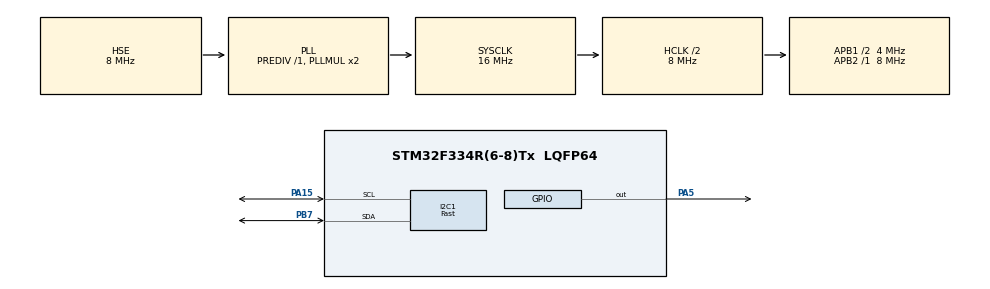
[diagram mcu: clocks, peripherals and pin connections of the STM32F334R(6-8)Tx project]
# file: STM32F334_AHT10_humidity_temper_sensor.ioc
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I2C1.I2C_Speed_Mode=I2C_Fast
I2C1.Timing=0x0000020B
Mcu.Family=STM32F3
Mcu.Name=STM32F334R(6-8)Tx
Mcu.Package=LQFP64
NVIC.I2C1_EV_IRQn=true\:0\:0\:false\:false\:true\:true\:true
NVIC.PriorityGroup=NVIC_PRIORITYGROUP_4
NVIC.TIM3_IRQn=true\:0\:0\:false\:false\:true\:true\:true
PA13.Mode=Serial_Wire
PA13.Signal=SYS_JTMS-SWDIO
PA14.Mode=Serial_Wire
PA14.Signal=SYS_JTCK-SWCLK
PA15.Mode=I2C
PA15.Signal=I2C1_SCL
PA5.Signal=GPIO_Output
PB7.Mode=I2C
PB7.Signal=I2C1_SDA
PF0\ /\ OSC_IN.Mode=HSE-External-Clock-Source
PF0\ /\ OSC_IN.Signal=RCC_OSC_IN
ProjectManager.HeapSize=0x200
ProjectManager.StackSize=0x400
ProjectManager.TargetToolchain=STM32CubeIDE
RCC.AHBCLKDivider=RCC_SYSCLK_DIV2
RCC.AHBFreq_Value=8000000
RCC.APB1CLKDivider=RCC_HCLK_DIV2
RCC.APB1Freq_Value=4000000
RCC.APB1TimFreq_Value=8000000
RCC.APB2Freq_Value=8000000
RCC.APB2TimFreq_Value=8000000
RCC.CortexFreq_Value=8000000
RCC.HCLKFreq_Value=8000000
RCC.HSE_VALUE=8000000
RCC.HSI_VALUE=8000000
RCC.LSE_VALUE=32768
RCC.PLLSourceVirtual=RCC_PLLSOURCE_HSE
RCC.SYSCLKFreq_VALUE=16000000
RCC.SYSCLKSourceVirtual=RCC_SYSCLKSOURCE_PLLCLK
TIM3.Period=1000-1
TIM3.Prescaler=800-1
VP_TIM3_VS_ClockSourceINT.Mode=Internal
board=custom

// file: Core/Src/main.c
/* USER CODE BEGIN Header */
/**
 ******************************************************************************
 * @file           : main.c
 * @brief          : Main program body
 ******************************************************************************
 * @attention
 *
 * <h2><center>&copy; Copyright (c) 2020 STMicroelectronics.
 * All rights reserved.</center></h2>
 *
 * This software component is licensed by ST under BSD 3-Clause license,
 * the "License"; You may not use this file except in compliance with the
 * License. You may obtain a copy of the License at:
 *                        opensource.org/licenses/BSD-3-Clause
 *
 ******************************************************************************
 */
/* USER CODE END Header */
#include "main.h"

I2C_HandleTypeDef hi2c1;

TIM_HandleTypeDef htim3;

/* USER CODE BEGIN PV */

/*Змінні необхідні для AHT10*/
uint8_t AHT10_RX_Data[6];
uint32_t AHT10_ADC_RAW;
float AHT10_Temperature;
float AHT10_Humidity;
uint8_t AHT10_TmpHumCmd[3] = { 0xAC, 0x33, 0x00 };

#define AHT10_ADDRESS (0x38 << 1)

/*Додаткові змінні*/
uint8_t T_100ms = 255;
uint8_t AHT10_Switcher = 255;

/* USER CODE END PV */

void SystemClock_Config(void);
static void MX_GPIO_Init(void);
static void MX_I2C1_Init(void);
static void MX_TIM3_Init(void);

/* USER CODE BEGIN 0 */
void HAL_TIM_PeriodElapsedCallback(TIM_HandleTypeDef *htim) {
	if (htim->Instance == TIM3) {
		T_100ms = 255;

	}
}
/* USER CODE END 0 */

int main(void) {

	/* MCU Configuration--------------------------------------------------------*/

	/* Reset of all peripherals, Initializes the Flash interface and the Systick. */
	HAL_Init();

	/* Configure the system clock */
	SystemClock_Config();

	/* Initialize all configured peripherals */
	MX_GPIO_Init();
	MX_I2C1_Init();
	MX_TIM3_Init();
	/* USER CODE BEGIN 2 */
	HAL_TIM_Base_Start_IT(&htim3);
	/* USER CODE END 2 */

	/* Infinite loop */
	/* USER CODE BEGIN WHILE */
	while (1) {

		if (T_100ms) {
			if (AHT10_Switcher) {
				HAL_I2C_Master_Transmit_IT(&hi2c1, AHT10_ADDRESS,
						(uint8_t*) AHT10_TmpHumCmd, 3);
			} else {
				HAL_I2C_Master_Receive_IT(&hi2c1, AHT10_ADDRESS,
						(uint8_t*) AHT10_RX_Data, 6);

			}

			if (~AHT10_RX_Data[0] & 0x80) {
				/* Convert to Temperature in °C */
				AHT10_ADC_RAW = (((uint32_t) AHT10_RX_Data[3] & 15) << 16)
						| ((uint32_t) AHT10_RX_Data[4] << 8) | AHT10_RX_Data[5];
				AHT10_Temperature =
						(float) (AHT10_ADC_RAW * 200.00 / 1048576.00) - 50.00;
				/* Convert to Relative Humidity in % */
				AHT10_ADC_RAW = ((uint32_t) AHT10_RX_Data[1] << 12)
						| ((uint32_t) AHT10_RX_Data[2] << 4)
						| (AHT10_RX_Data[3] >> 4);
				AHT10_Humidity = (float) (AHT10_ADC_RAW * 100.00 / 1048576.00);
			}

			/* Invert */
			AHT10_Switcher = ~AHT10_Switcher;
			/* Nullify */
			T_100ms = 0;
			GPIOA->ODR ^= GPIO_PIN_5;
		}

		/* USER CODE END WHILE */

	}
}

void SystemClock_Config(void) {
	RCC_OscInitTypeDef RCC_OscInitStruct = { 0 };
	RCC_ClkInitTypeDef RCC_ClkInitStruct = { 0 };
	RCC_PeriphCLKInitTypeDef PeriphClkInit = { 0 };

	/** Initializes the RCC Oscillators according to the specified parameters
	 * in the RCC_OscInitTypeDef structure.
	 */
	RCC_OscInitStruct.OscillatorType = RCC_OSCILLATORTYPE_HSI
			| RCC_OSCILLATORTYPE_HSE;
	RCC_OscInitStruct.HSEState = RCC_HSE_BYPASS;
	RCC_OscInitStruct.HSEPredivValue = RCC_HSE_PREDIV_DIV1;
	RCC_OscInitStruct.HSIState = RCC_HSI_ON;
	RCC_OscInitStruct.HSICalibrationValue = RCC_HSICALIBRATION_DEFAULT;
	RCC_OscInitStruct.PLL.PLLState = RCC_PLL_ON;
	RCC_OscInitStruct.PLL.PLLSource = RCC_PLLSOURCE_HSE;
	RCC_OscInitStruct.PLL.PLLMUL = RCC_PLL_MUL2;
	if (HAL_RCC_OscConfig(&RCC_OscInitStruct) != HAL_OK) {
		Error_Handler();
	}
	/** Initializes the CPU, AHB and APB buses clocks
	 */
	RCC_ClkInitStruct.ClockType = RCC_CLOCKTYPE_HCLK | RCC_CLOCKTYPE_SYSCLK
			| RCC_CLOCKTYPE_PCLK1 | RCC_CLOCKTYPE_PCLK2;
	RCC_ClkInitStruct.SYSCLKSource = RCC_SYSCLKSOURCE_PLLCLK;
	RCC_ClkInitStruct.AHBCLKDivider = RCC_SYSCLK_DIV2;
	RCC_ClkInitStruct.APB1CLKDivider = RCC_HCLK_DIV2;
	RCC_ClkInitStruct.APB2CLKDivider = RCC_HCLK_DIV1;

	if (HAL_RCC_ClockConfig(&RCC_ClkInitStruct, FLASH_LATENCY_0) != HAL_OK) {
		Error_Handler();
	}
	PeriphClkInit.PeriphClockSelection = RCC_PERIPHCLK_I2C1;
	PeriphClkInit.I2c1ClockSelection = RCC_I2C1CLKSOURCE_HSI;
	if (HAL_RCCEx_PeriphCLKConfig(&PeriphClkInit) != HAL_OK) {
		Error_Handler();
	}
}

static void MX_I2C1_Init(void) {

	hi2c1.Instance = I2C1;
	hi2c1.Init.Timing = 0x0000020B;
	hi2c1.Init.OwnAddress1 = 0;
	hi2c1.Init.AddressingMode = I2C_ADDRESSINGMODE_7BIT;
	hi2c1.Init.DualAddressMode = I2C_DUALADDRESS_DISABLE;
	hi2c1.Init.OwnAddress2 = 0;
	hi2c1.Init.OwnAddress2Masks = I2C_OA2_NOMASK;
	hi2c1.Init.GeneralCallMode = I2C_GENERALCALL_DISABLE;
	hi2c1.Init.NoStretchMode = I2C_NOSTRETCH_DISABLE;
	if (HAL_I2C_Init(&hi2c1) != HAL_OK) {
		Error_Handler();
	}
	/** Configure Analogue filter
	 */
	if (HAL_I2CEx_ConfigAnalogFilter(&hi2c1, I2C_ANALOGFILTER_ENABLE)
			!= HAL_OK) {
		Error_Handler();
	}
	/** Configure Digital filter
	 */
	if (HAL_I2CEx_ConfigDigitalFilter(&hi2c1, 0) != HAL_OK) {
		Error_Handler();
	}

}

static void MX_TIM3_Init(void) {

	TIM_ClockConfigTypeDef sClockSourceConfig = { 0 };
	TIM_MasterConfigTypeDef sMasterConfig = { 0 };

	htim3.Instance = TIM3;
	htim3.Init.Prescaler = 800 - 1;
	htim3.Init.CounterMode = TIM_COUNTERMODE_UP;
	htim3.Init.Period = 1000 - 1;
	htim3.Init.ClockDivision = TIM_CLOCKDIVISION_DIV1;
	htim3.Init.AutoReloadPreload = TIM_AUTORELOAD_PRELOAD_DISABLE;
	if (HAL_TIM_Base_Init(&htim3) != HAL_OK) {
		Error_Handler();
	}
	sClockSourceConfig.ClockSource = TIM_CLOCKSOURCE_INTERNAL;
	if (HAL_TIM_ConfigClockSource(&htim3, &sClockSourceConfig) != HAL_OK) {
		Error_Handler();
	}
	sMasterConfig.MasterOutputTrigger = TIM_TRGO_RESET;
	sMasterConfig.MasterSlaveMode = TIM_MASTERSLAVEMODE_DISABLE;
	if (HAL_TIMEx_MasterConfigSynchronization(&htim3, &sMasterConfig)
			!= HAL_OK) {
		Error_Handler();
	}

}

static void MX_GPIO_Init(void) {
	GPIO_InitTypeDef GPIO_InitStruct = { 0 };

	/* GPIO Ports Clock Enable */
	__HAL_RCC_GPIOF_CLK_ENABLE();
	__HAL_RCC_GPIOA_CLK_ENABLE();
	__HAL_RCC_GPIOB_CLK_ENABLE();

	/*Configure GPIO pin Output Level */
	HAL_GPIO_WritePin(GPIOA, GPIO_PIN_5, GPIO_PIN_RESET);

	/*Configure GPIO pin : PA5 */
	GPIO_InitStruct.Pin = GPIO_PIN_5;
	GPIO_InitStruct.Mode = GPIO_MODE_OUTPUT_PP;
	GPIO_InitStruct.Pull = GPIO_NOPULL;
	GPIO_InitStruct.Speed = GPIO_SPEED_FREQ_LOW;
	HAL_GPIO_Init(GPIOA, &GPIO_InitStruct);

}

void Error_Handler(void) {
}

/************************ (C) COPYRIGHT STMicroelectronics *****END OF FILE****/
